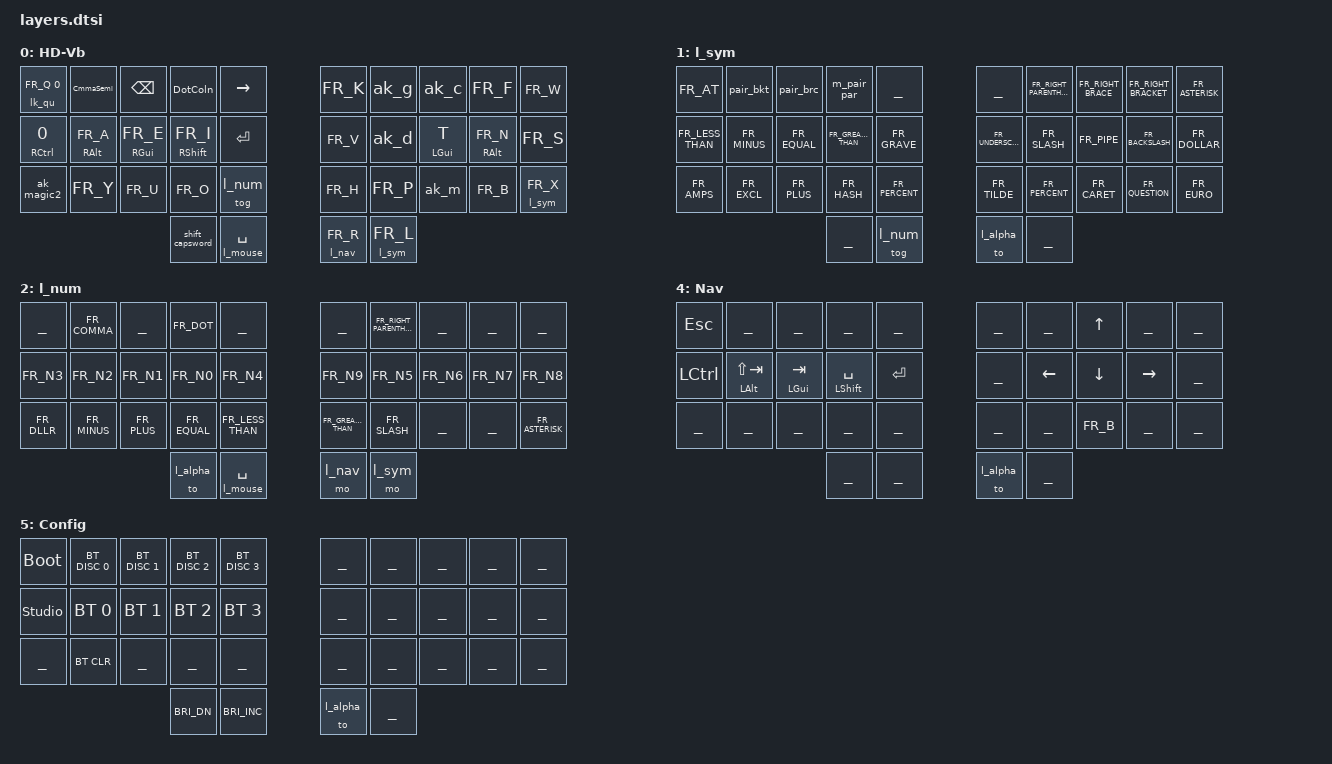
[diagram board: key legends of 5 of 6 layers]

/ {
    keymap {
        compatible = "zmk,keymap"; 
        l_alpha {											
            display-name = "HD-Vb";							
            bindings = <	
                &lk_qu FR_Q 0	&CmmaSemi	&kp BACKSPACE	&DotColn	&kp RIGHT	&kp FR_K 	&ak_g	&ak_c	&kp FR_F &kp FR_W
                &hrm_apos RCTRL 0	&hmv RALT FR_A	&hrm_e RGUI FR_E	&hmv RSHFT FR_I	&kp ENTER	 &kp FR_V	&ak_d  	&hmc LGUI T 	&hmc RALT FR_N    &kp FR_S
                &ak_magic2	&kp FR_Y 	&kp FR_U	&kp FR_O	&tog l_num	&kp FR_H	&kp FR_P 	&ak_m	&kp FR_B    &ltm l_sym FR_X
                                &shift_capsword   	&ltm l_mouse SPACE	&ltm l_nav FR_R	&ltm l_sym FR_L  
            >;											
        };
	
        Symbols {    
            display-name = "l_sym";
            bindings = <
                &kp FR_AT	&pair_bkt	&pair_brc	&m_pair_par	______	______	&kp FR_RIGHT_PARENTHESIS	&kp FR_RIGHT_BRACE	&kp FR_RIGHT_BRACKET	&kp FR_ASTERISK
                &kp FR_LESS_THAN     &kp FR_MINUS	&kp FR_EQUAL	&kp FR_GREATER_THAN	&kp FR_GRAVE	&kp FR_UNDERSCORE &kp FR_SLASH	&kp FR_PIPE	&kp FR_BACKSLASH	&kp FR_DOLLAR	
                &kp FR_AMPS     &kp FR_EXCL	&kp FR_PLUS	&kp FR_HASH	&kp FR_PERCENT	&kp FR_TILDE	&kp FR_PERCENT	&kp FR_CARET	&kp FR_QUESTION	&kp FR_EURO
                            ______	&tog l_num	&to l_alpha	______
            >;
        };

        Numbers {
            display-name = "l_num";
            bindings = <
                ______	&kp FR_COMMA		______ &kp FR_DOT	______	______	&kp FR_RIGHT_PARENTHESIS	______	______	______	
                &kp FR_N3    &kp FR_N2    &kp FR_N1     &kp FR_N0    &kp FR_N4    &kp FR_N9    &kp FR_N5    &kp FR_N6    &kp FR_N7    &kp FR_N8
                &kp FR_DLLR	&kp FR_MINUS	&kp FR_PLUS	&kp FR_EQUAL	&kp FR_LESS_THAN	&kp FR_GREATER_THAN	&kp FR_SLASH	______	______	&kp FR_ASTERISK	
                                        &to l_alpha	&lt l_mouse SPACE	&mo l_nav	&mo l_sym
            >;
        };


        Mouse {    
            display-name = "l_mouse";
            bindings = <
                &kp ESCAPE	&kp HYPER(TAB)	&kp META(TAB)	______	&kp LG(LS(SPACE))	            &kp LG(LA(LC(FR_A))) &kp LG(LA(LC(FR_B))) &kp LG(LA(LC(FR_C))) &kp LG(LA(LC(FR_D))) &kp LG(LA(LC(FR_E))) 
                &kp LG(FR_A)	&kp LS(TAB)	&kp TAB   &kp LG(SPACE) ______                          &kp LG(LA(LC(FR_F))) &kp LG(LA(LC(FR_G))) &kp LG(LA(LC(FR_H))) &kp LG(LA(LC(FR_I))) &kp LG(LA(LC(FR_J))) 
                &kp LG(FR_Z)	&kp LG(FR_X)	&kp LG(FR_C)	&kp LG(FR_V)	&kp LS(LG(FR_V))    &kp LG(LA(LC(FR_K))) &kp LG(LA(LC(FR_L))) &kp LG(LA(LC(FR_M))) &kp LG(LA(LC(FR_N))) &kp LG(LA(LC(FR_O))) 
                            &to l_alpha	&tog l_mouse	&to l_alpha	______
            >;
        };

        Nav {            // Toggle
            bindings = <
                &kp ESCAPE	______	______	______	______	                     ______	______	&kp UP	    ______	______	 
                &kp LCTRL   &hmr_nav LALT LS(TAB)	&hmr_nav LGUI TAB	&hmr_nav LSHIFT SPACE	&kp ENTER	 ______	&kp LEFT	&kp DOWN	&kp RIGHT	______	
                ______	______	______	______	______	             ______	______	&kp FR_B	______	______	       	
                                ______	______	&to l_alpha	______	
            >;
        };

        Config {
            bindings = <
                &bootloader	&bt BT_DISC 0	&bt BT_DISC 1	&bt BT_DISC 2	&bt BT_DISC 3	______	______	______	______	______
                &studio_unlock	&bt BT_SEL 0	&bt BT_SEL 1	&bt BT_SEL 2	&bt BT_SEL 3	______	______	______	______	______
                ______	&bt BT_CLR	______	______	______	______	______	______	______	______
                            &kp C_BRI_DN	&kp C_BRI_INC   &to l_alpha	______
            >;

        };

    };
};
